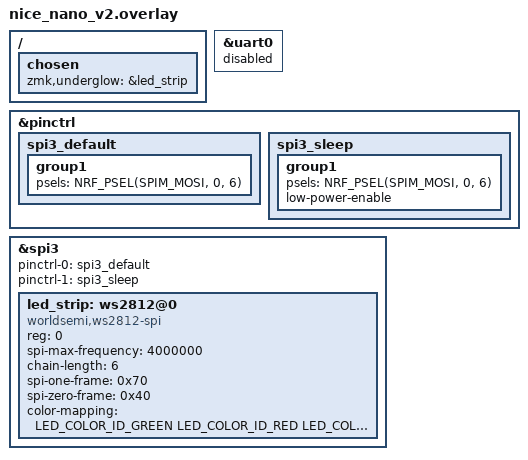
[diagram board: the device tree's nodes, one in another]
/*
 * Copyright (c) 2024 The ZMK Contributors
 * SPDX-License-Identifier: MIT
 */

&uart0 {
  status = "disabled";
};

&pinctrl {
  spi3_default: spi3_default {
    group1 {
      psels = <NRF_PSEL(SPIM_MOSI, 0, 6)>;
    };
  };

  spi3_sleep: spi3_sleep {
    group1 {
      psels = <NRF_PSEL(SPIM_MOSI, 0, 6)>;
      low-power-enable;
    };
  };
};

spi_led_strip: &spi3 {
  pinctrl-0 = <&spi3_default>;
  pinctrl-1 = <&spi3_sleep>;
  pinctrl-names = "default", "sleep";
  status = "okay";
  led_strip: ws2812@0 {
    compatible = "worldsemi,ws2812-spi";

    /* SPI */
    reg = <0>; /* ignored, but necessary for SPI bindings */
    spi-max-frequency = <4000000>;

    /* WS2812 */
    chain-length = <6>; /* 6 keys have underglow at the moment */
    spi-one-frame = <0x70>;
    spi-zero-frame = <0x40>;

    color-mapping = <LED_COLOR_ID_GREEN LED_COLOR_ID_RED LED_COLOR_ID_BLUE>;
  };
};


/ {
  chosen {
    zmk,underglow = &led_strip;
  };
};
